# RX64M_S12AD_Pilot register map
File version: 1.0
RX64M_S12AD_Pilot peripheral registers generated from iodefine.h (pilot).
Registers are 16-bit, read-write, reset 0x0 unless marked. A register's access mark holds for its fields unless they carry their own. Offsets are from the block's base; lines under a group give offsets from that group; [hi:lo] are bit positions; {n}, {i} and the like mark numbered series; 'fields as' and 'values as' point back to an identical list; <NAME> marks a mode.

## Memory map
0x00089000 S12AD size 0xA2
0x00089100 S12AD1 size 0xA5

## S12AD
Base 0x00089000
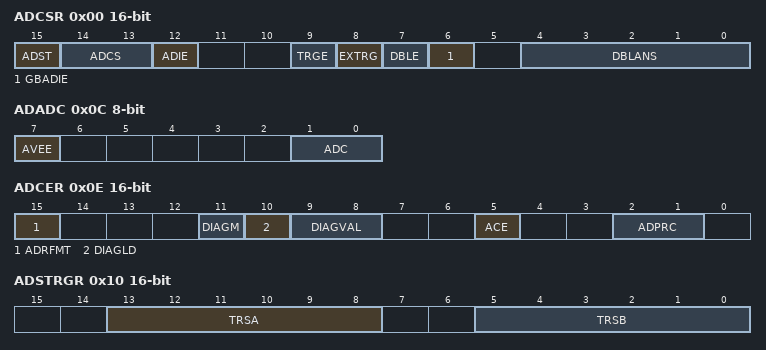
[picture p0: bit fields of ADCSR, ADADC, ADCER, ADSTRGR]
0x00 ADCSR
  [15] ADST, [14:13] ADCS, [12] ADIE, [9] TRGE, [8] EXTRG, [7] DBLE, [6] GBADIE, [4:0] DBLANS
0x04 ADANSA0
  [15:0] ANSA0
0x08 ADADS0
  [15:0] ADS0
0x0C ADADC 8-bit
  [7] AVEE, [1:0] ADC
0x0E ADCER
  [15] ADRFMT, [11] DIAGM, [10] DIAGLD, [9:8] DIAGVAL, [5] ACE, [2:1] ADPRC
0x10 ADSTRGR
  [13:8] TRSA, [5:0] TRSB
0x14 ADANSB0
  [15:0] ANSB0
0x18 ADDBLDR ro
  [13:2] AD
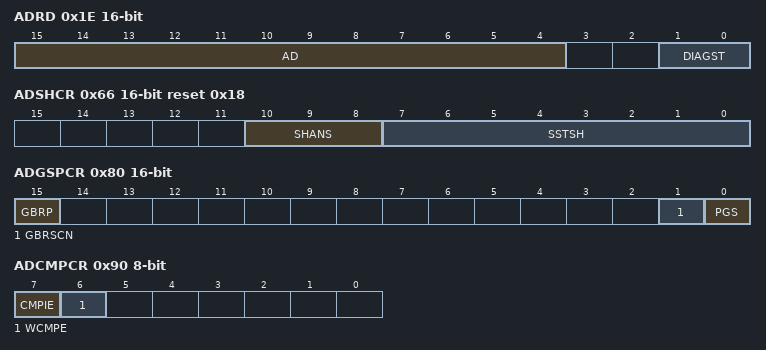
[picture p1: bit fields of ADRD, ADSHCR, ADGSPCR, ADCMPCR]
0x1E ADRD ro
  [15:4] AD, [1:0] DIAGST
{0x20+2i} ADDR{i} ro (i=0..7)
0x60 ADSSTR0 8-bit reset 0xB
0x66 ADSHCR reset 0x18
  [10:8] SHANS, [7:0] SSTSH
{0x72+i} ADSSTR{i} 8-bit reset 0xB (i=1..7)
0x7A ADDISCR 8-bit
  [4:0] ADNDIS
0x7C ADSHMSR 8-bit reset 0x8
  [0] SHMD
0x80 ADGSPCR
  [15] GBRP, [1] GBRSCN, [0] PGS
0x84 ADDBLDRA ro
0x86 ADDBLDRB ro
0x90 ADCMPCR 8-bit
  [7] CMPIE, [6] WCMPE
0x94 ADCMPANSR0
  [15:0] CMPS0
0x98 ADCMPLR0
  [15:0] CMPL0
0x9C ADCMPDR0
0x9E ADCMPDR1
0xA0 ADCMPSR0
  [15:0] CMPF0

## S12AD1
Base 0x00089100
Registers as S12AD, without ADSHCR, ADSHMSR; these are added or differ:
0x06 ADANSA1
  [4:0] ANSA1
0x0A ADADS1
  [4:0] ADS1
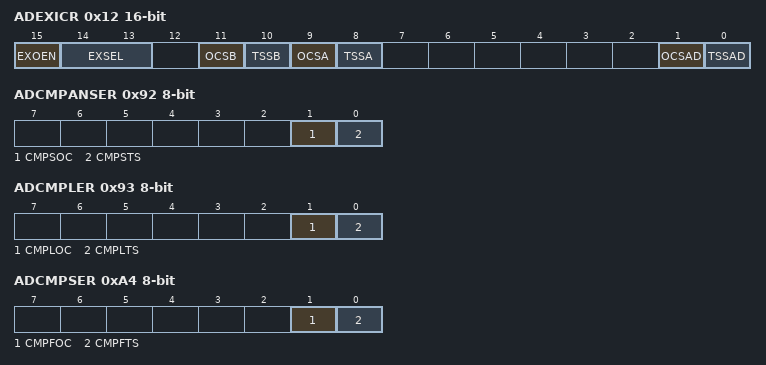
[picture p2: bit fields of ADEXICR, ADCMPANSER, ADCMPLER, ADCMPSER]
0x12 ADEXICR
  [15] EXOEN, [14:13] EXSEL, [11] OCSB, [10] TSSB, [9] OCSA, [8] TSSA, [1] OCSAD, [0] TSSAD
0x16 ADANSB1
  [4:0] ANSB1
0x18 ADDBLDR ro
0x1A ADTSDR ro
0x1C ADOCDR ro
{0x20+2i} ADDR{i} ro (i=8..20)
0x61 ADSSTRL 8-bit reset 0xB
0x70 ADSSTRT 8-bit reset 0xB
0x71 ADSSTRO 8-bit reset 0xB
0x92 ADCMPANSER 8-bit
  [1] CMPSOC, [0] CMPSTS
0x93 ADCMPLER 8-bit
  [1] CMPLOC, [0] CMPLTS
0x96 ADCMPANSR1
  [4:0] CMPS1
0x9A ADCMPLR1
  [4:0] CMPL1
0xA2 ADCMPSR1
  [4:0] CMPF1
0xA4 ADCMPSER 8-bit
  [1] CMPFOC, [0] CMPFTS
